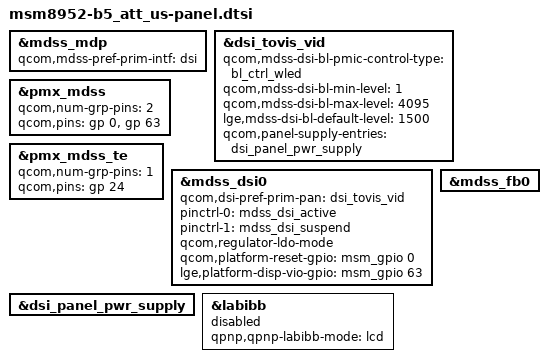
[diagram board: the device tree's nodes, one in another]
/*
 * Copyright (c) 2015, The Linux Foundation. All rights reserved.
 *
 * This program is free software; you can redistribute it and/or modify
 * it under the terms of the GNU General Public License version 2 and
 * only version 2 as published by the Free Software Foundation.
 *
 * This program is distributed in the hope that it will be useful,
 * but WITHOUT ANY WARRANTY; without even the implied warranty of
 * MERCHANTABILITY or FITNESS FOR A PARTICULAR PURPOSE.  See the
 * GNU General Public License for more details.
 */

#include "../dsi-panel-tovis-nt51021-wuxga-video.dtsi"

&mdss_mdp {
	qcom,mdss-pref-prim-intf = "dsi";
};

&dsi_tovis_vid {
	qcom,mdss-dsi-bl-pmic-control-type = "bl_ctrl_wled";
	qcom,mdss-dsi-bl-min-level = <1>;
	qcom,mdss-dsi-bl-max-level = <4095>;
	lge,mdss-dsi-bl-default-level = <1500>;
	qcom,panel-supply-entries = <&dsi_panel_pwr_supply>;
};

&pmx_mdss {
       qcom,num-grp-pins = <2>;
       qcom,pins = <&gp 0>, <&gp 63>;
};

&pmx_mdss_te {
	qcom,num-grp-pins = <1>;
	qcom,pins = <&gp 24>;
};

&mdss_dsi0 {
	qcom,dsi-pref-prim-pan = <&dsi_tovis_vid>;
	pinctrl-names = "mdss_default", "mdss_sleep";
	pinctrl-0 = <&mdss_dsi_active>;
	pinctrl-1 = <&mdss_dsi_suspend>;
	qcom,regulator-ldo-mode;
	qcom,platform-reset-gpio = <&msm_gpio 0 0>;
	lge,platform-disp-vio-gpio = <&msm_gpio 63 0>;
	/delete-property/ vdd-supply;
	/delete-property/ lab-supply;
	/delete-property/ 	ibb-supply;
};

&dsi_panel_pwr_supply {
	/delete-node/ qcom,panel-supply-entry@0;
	/delete-node/ qcom,panel-supply-entry@2;
	/delete-node/ qcom,panel-supply-entry@3;
};


&labibb {
	status = "disable";
	qpnp,qpnp-labibb-mode = "lcd";
};

&mdss_fb0 {
	/delete-property/ qcom,mdss-fb-splash-logo-enabled;
};
